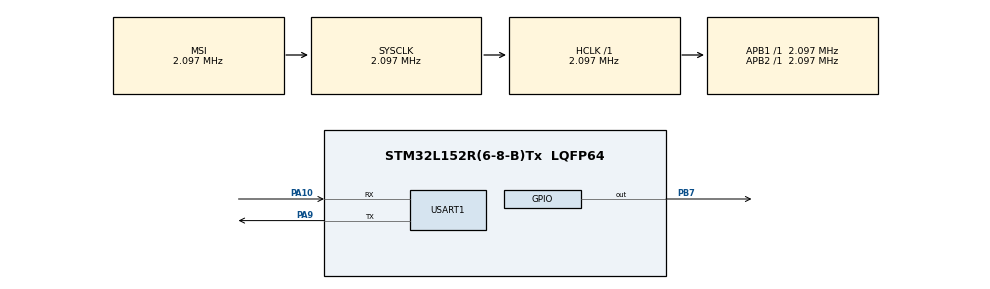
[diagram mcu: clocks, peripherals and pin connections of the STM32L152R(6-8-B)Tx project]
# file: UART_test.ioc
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Mcu.Family=STM32L1
Mcu.Name=STM32L152R(6-8-B)Tx
Mcu.Package=LQFP64
NVIC.PriorityGroup=NVIC_PRIORITYGROUP_4
NVIC.USART1_IRQn=true\:0\:0\:false\:false\:true\:true\:true
PA10.Mode=Asynchronous
PA10.Signal=USART1_RX
PA9.Mode=Asynchronous
PA9.Signal=USART1_TX
PB7.Signal=GPIO_Output
PH0-OSC_IN.Mode=HSE-External-Oscillator
PH0-OSC_IN.Signal=RCC_OSC_IN
PH1-OSC_OUT.Mode=HSE-External-Oscillator
PH1-OSC_OUT.Signal=RCC_OSC_OUT
ProjectManager.HeapSize=0x200
ProjectManager.StackSize=0x400
ProjectManager.TargetToolchain=STM32CubeIDE
RCC.AHBFreq_Value=2097000
RCC.APB1Freq_Value=2097000
RCC.APB2Freq_Value=2097000
RCC.HSE_VALUE=24000000
RCC.HSI_VALUE=16000000
RCC.LSE_VALUE=32768
RCC.MSI_VALUE=2097000
RCC.SYSCLKFreq_VALUE=2097000
RCC.VCOOutputFreq_Value=48000000
USART1.VirtualMode=VM_ASYNC
board=custom

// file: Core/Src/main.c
/* USER CODE BEGIN Header */
/**
  ******************************************************************************
  * @file           : main.c
  * @brief          : Main program body
  ******************************************************************************
  * @attention
  *
  * Copyright (c) 2022 STMicroelectronics.
  * All rights reserved.
  *
  * This software is licensed under terms that can be found in the LICENSE file
  * in the root directory of this software component.
  * If no LICENSE file comes with this software, it is provided AS-IS.
  *
  ******************************************************************************
  */
/* USER CODE END Header */
#include <stdbool.h>
#include "main.h"

UART_HandleTypeDef huart1;

/* USER CODE BEGIN PV */
uint8_t* txdata;
static bool received = false;
/* USER CODE END PV */

void SystemClock_Config(void);
static void MX_GPIO_Init(void);
static void MX_USART1_UART_Init(void);

int main(void)
{

  /* MCU Configuration--------------------------------------------------------*/

  /* Reset of all peripherals, Initializes the Flash interface and the Systick. */
  HAL_Init();

  /* Configure the system clock */
  SystemClock_Config();

  /* Initialize all configured peripherals */
  MX_GPIO_Init();
  MX_USART1_UART_Init();
  /* USER CODE BEGIN 2 */

	HAL_GPIO_WritePin(GPIOB, GPIO_PIN_7, GPIO_PIN_SET);

  /* USER CODE END 2 */

  /* Infinite loop */
  /* USER CODE BEGIN WHILE */
//  while (1)
//  {
    /* USER CODE END WHILE */

    /* USER CODE BEGIN 3 */
	  uint8_t input[1] = "a";
	  uint8_t output[1];
//	  if (!received) {
		  int send_val = HAL_UART_Transmit_IT(&huart1, input, sizeof(input));
//		  while(HAL_UART_GetState(&huart1) == HAL_UART_STATE_BUSY_TX || HAL_UART_GetState(&huart1) == HAL_UART_STATE_BUSY_TX_RX) {} // transmitting
		  // finish transmitting
		  int rec_val = HAL_UART_Receive_IT(&huart1, output, sizeof(output));
//	  }

//	  HAL_GPIO_WritePin(GPIOB, GPIO_PIN_7, GPIO_PIN_RESET);
//	  HAL_Delay(100);
//	  int ret_val = HAL_UART_Receive(&huart1, output, sizeof(output), 1000);

  }
  /* USER CODE END 3 */
//}

void SystemClock_Config(void)
{
  RCC_OscInitTypeDef RCC_OscInitStruct = {0};
  RCC_ClkInitTypeDef RCC_ClkInitStruct = {0};

  /** Configure the main internal regulator output voltage
  */
  __HAL_PWR_VOLTAGESCALING_CONFIG(PWR_REGULATOR_VOLTAGE_SCALE1);
  /** Initializes the RCC Oscillators according to the specified parameters
  * in the RCC_OscInitTypeDef structure.
  */
  RCC_OscInitStruct.OscillatorType = RCC_OSCILLATORTYPE_MSI;
  RCC_OscInitStruct.MSIState = RCC_MSI_ON;
  RCC_OscInitStruct.MSICalibrationValue = 0;
  RCC_OscInitStruct.MSIClockRange = RCC_MSIRANGE_5;
  RCC_OscInitStruct.PLL.PLLState = RCC_PLL_NONE;
  if (HAL_RCC_OscConfig(&RCC_OscInitStruct) != HAL_OK)
  {
    Error_Handler();
  }
  /** Initializes the CPU, AHB and APB buses clocks
  */
  RCC_ClkInitStruct.ClockType = RCC_CLOCKTYPE_HCLK|RCC_CLOCKTYPE_SYSCLK
                              |RCC_CLOCKTYPE_PCLK1|RCC_CLOCKTYPE_PCLK2;
  RCC_ClkInitStruct.SYSCLKSource = RCC_SYSCLKSOURCE_MSI;
  RCC_ClkInitStruct.AHBCLKDivider = RCC_SYSCLK_DIV1;
  RCC_ClkInitStruct.APB1CLKDivider = RCC_HCLK_DIV1;
  RCC_ClkInitStruct.APB2CLKDivider = RCC_HCLK_DIV1;

  if (HAL_RCC_ClockConfig(&RCC_ClkInitStruct, FLASH_LATENCY_0) != HAL_OK)
  {
    Error_Handler();
  }
}

static void MX_USART1_UART_Init(void)
{

  huart1.Instance = USART1;
  huart1.Init.BaudRate = 115200;
  huart1.Init.WordLength = UART_WORDLENGTH_8B;
  huart1.Init.StopBits = UART_STOPBITS_1;
  huart1.Init.Parity = UART_PARITY_NONE;
  huart1.Init.Mode = UART_MODE_TX_RX;
  huart1.Init.HwFlowCtl = UART_HWCONTROL_NONE;
  huart1.Init.OverSampling = UART_OVERSAMPLING_16;
  if (HAL_UART_Init(&huart1) != HAL_OK)
  {
    Error_Handler();
  }

}

static void MX_GPIO_Init(void)
{
  GPIO_InitTypeDef GPIO_InitStruct = {0};

  /* GPIO Ports Clock Enable */
  __HAL_RCC_GPIOH_CLK_ENABLE();
  __HAL_RCC_GPIOA_CLK_ENABLE();
  __HAL_RCC_GPIOB_CLK_ENABLE();

  /*Configure GPIO pin Output Level */
  HAL_GPIO_WritePin(GPIOB, GPIO_PIN_7, GPIO_PIN_RESET);

  /*Configure GPIO pin : PB7 */
  GPIO_InitStruct.Pin = GPIO_PIN_7;
  GPIO_InitStruct.Mode = GPIO_MODE_OUTPUT_PP;
  GPIO_InitStruct.Pull = GPIO_NOPULL;
  GPIO_InitStruct.Speed = GPIO_SPEED_FREQ_LOW;
  HAL_GPIO_Init(GPIOB, &GPIO_InitStruct);

}

/* USER CODE BEGIN 4 */

void HAL_UART_TxCpltCallback(UART_HandleTypeDef *huart)
{
//	HAL_GPIO_WritePin(GPIOB, GPIO_PIN_7, GPIO_PIN_SET);
}

void HAL_UART_RxCpltCallback(UART_HandleTypeDef *huart)
{
	HAL_GPIO_WritePin(GPIOB, GPIO_PIN_7, GPIO_PIN_RESET);
//	received = true;
}

/* USER CODE END 4 */

void Error_Handler(void)
{
  __disable_irq();
  while (1)
  {
  }
}
